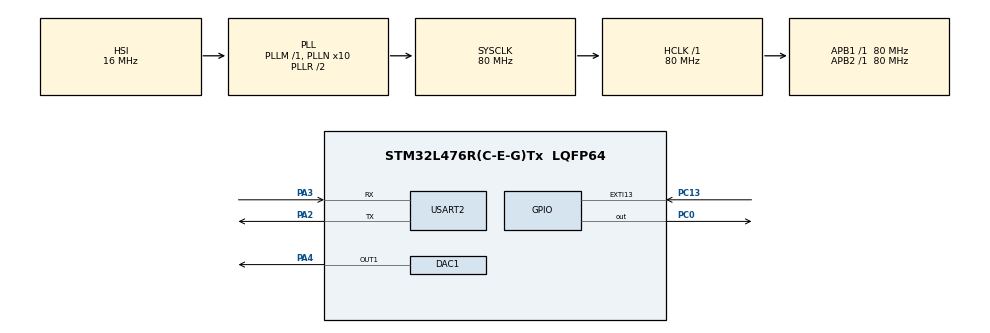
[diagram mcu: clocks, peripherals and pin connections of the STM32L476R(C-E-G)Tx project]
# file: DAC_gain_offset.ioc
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DAC1.DAC_OutputBuffer-DAC_OUT1=DAC_OUTPUTBUFFER_DISABLE
DAC1.DAC_Trigger-DAC_OUT1=DAC_TRIGGER_NONE
Mcu.Family=STM32L4
Mcu.Name=STM32L476R(C-E-G)Tx
Mcu.Package=LQFP64
NVIC.EXTI15_10_IRQn=true\:1\:0\:true\:false\:true\:true\:true\:true
NVIC.PriorityGroup=NVIC_PRIORITYGROUP_4
NVIC.TIM2_IRQn=true\:2\:0\:true\:false\:true\:true\:true\:true
NVIC.TIM6_DAC_IRQn=true\:2\:0\:true\:false\:true\:true\:true\:true
NVIC.USART2_IRQn=true\:0\:0\:false\:false\:true\:true\:true\:true
PA2.Mode=Asynchronous
PA2.Signal=USART2_TX
PA3.Mode=Asynchronous
PA3.Signal=USART2_RX
PA4.Signal=COMP_DAC11_group
PC0.Signal=GPIO_Output
PC13.Signal=GPXTI13
ProjectManager.HeapSize=0x200
ProjectManager.StackSize=0x400
ProjectManager.TargetToolchain=STM32CubeIDE
RCC.ADCFreq_Value=64000000
RCC.AHBFreq_Value=80000000
RCC.APB1Freq_Value=80000000
RCC.APB1TimFreq_Value=80000000
RCC.APB2Freq_Value=80000000
RCC.APB2TimFreq_Value=80000000
RCC.CortexFreq_Value=80000000
RCC.HCLKFreq_Value=80000000
RCC.HSE_VALUE=8000000
RCC.HSI_VALUE=16000000
RCC.LSE_VALUE=32768
RCC.MSI_VALUE=4000000
RCC.PLLN=10
RCC.PLLSourceVirtual=RCC_PLLSOURCE_HSI
RCC.SYSCLKFreq_VALUE=80000000
RCC.SYSCLKSource=RCC_SYSCLKSOURCE_PLLCLK
RCC.USBFreq_Value=64000000
RCC.VCOOutputFreq_Value=160000000
SH.COMP_DAC11_group.0=DAC1_OUT1,DAC_OUT1
TIM2.Period=199
TIM2.Prescaler=199
USART2.VirtualMode-Asynchronous=VM_ASYNC
VP_TIM2_VS_ClockSourceINT.Mode=Internal
board=custom

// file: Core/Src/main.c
/* USER CODE BEGIN Header */
/**
  ******************************************************************************
  * @file           : main.c
  * @brief          : Main program body
  ******************************************************************************
  * @attention
  *
  * Copyright (c) 2026 STMicroelectronics.
  * All rights reserved.
  *
  * This software is licensed under terms that can be found in the LICENSE file
  * in the root directory of this software component.
  * If no LICENSE file comes with this software, it is provided AS-IS.
  *
  ******************************************************************************
  */
/* USER CODE END Header */
#include "main.h"
#include "dac.h"
#include "tim.h"
#include "usart.h"
#include "gpio.h"

/* USER CODE BEGIN Includes */
#include "callbacks.h"
/* USER CODE END Includes */

void SystemClock_Config(void);

int main(void)
{

  /* MCU Configuration--------------------------------------------------------*/

  /* Reset of all peripherals, Initializes the Flash interface and the Systick. */
  HAL_Init();

  /* Configure the system clock */
  SystemClock_Config();

  /* Initialize all configured peripherals */
  MX_GPIO_Init();
  MX_DAC1_Init();
  MX_TIM2_Init();
  MX_USART2_UART_Init();
  /* USER CODE BEGIN 2 */
  extern volatile uint8_t rx_data;
  HAL_DAC_Start(&hdac1, DAC_CHANNEL_1);
  HAL_GPIO_WritePin(GPIOC, GPIO_PIN_0, GPIO_PIN_RESET);
  HAL_UART_Receive_IT(&huart2, (uint8_t *)&rx_data, 1);
  /* USER CODE END 2 */

  /* Infinite loop */
  while (1)
  {

    /* USER CODE BEGIN 3 */
//HAL_GPIO_TogglePin(GPIOA, GPIO_PIN_5); // Cambia el estado del LED
	//  HAL_Delay(1000);
  }
  /* USER CODE END 3 */
}

void SystemClock_Config(void)
{
  RCC_OscInitTypeDef RCC_OscInitStruct = {0};
  RCC_ClkInitTypeDef RCC_ClkInitStruct = {0};

  /** Configure the main internal regulator output voltage
  */
  if (HAL_PWREx_ControlVoltageScaling(PWR_REGULATOR_VOLTAGE_SCALE1) != HAL_OK)
  {
    Error_Handler();
  }

  /** Initializes the RCC Oscillators according to the specified parameters
  * in the RCC_OscInitTypeDef structure.
  */
  RCC_OscInitStruct.OscillatorType = RCC_OSCILLATORTYPE_HSI;
  RCC_OscInitStruct.HSIState = RCC_HSI_ON;
  RCC_OscInitStruct.HSICalibrationValue = RCC_HSICALIBRATION_DEFAULT;
  RCC_OscInitStruct.PLL.PLLState = RCC_PLL_ON;
  RCC_OscInitStruct.PLL.PLLSource = RCC_PLLSOURCE_HSI;
  RCC_OscInitStruct.PLL.PLLM = 1;
  RCC_OscInitStruct.PLL.PLLN = 10;
  RCC_OscInitStruct.PLL.PLLP = RCC_PLLP_DIV7;
  RCC_OscInitStruct.PLL.PLLQ = RCC_PLLQ_DIV2;
  RCC_OscInitStruct.PLL.PLLR = RCC_PLLR_DIV2;
  if (HAL_RCC_OscConfig(&RCC_OscInitStruct) != HAL_OK)
  {
    Error_Handler();
  }

  /** Initializes the CPU, AHB and APB buses clocks
  */
  RCC_ClkInitStruct.ClockType = RCC_CLOCKTYPE_HCLK|RCC_CLOCKTYPE_SYSCLK
                              |RCC_CLOCKTYPE_PCLK1|RCC_CLOCKTYPE_PCLK2;
  RCC_ClkInitStruct.SYSCLKSource = RCC_SYSCLKSOURCE_PLLCLK;
  RCC_ClkInitStruct.AHBCLKDivider = RCC_SYSCLK_DIV1;
  RCC_ClkInitStruct.APB1CLKDivider = RCC_HCLK_DIV1;
  RCC_ClkInitStruct.APB2CLKDivider = RCC_HCLK_DIV1;

  if (HAL_RCC_ClockConfig(&RCC_ClkInitStruct, FLASH_LATENCY_4) != HAL_OK)
  {
    Error_Handler();
  }
}

void Error_Handler(void)
{
  __disable_irq();
  while (1)
  {
  }
}
